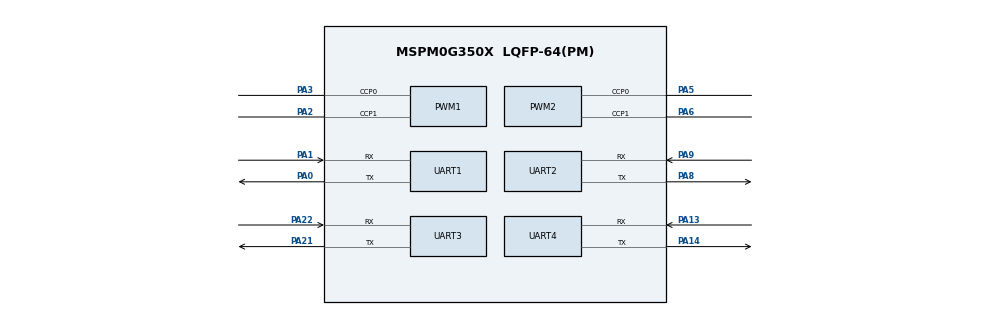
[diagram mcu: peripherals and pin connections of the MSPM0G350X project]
/**
 * @cliArgs --device "MSPM0G350X" --part "Default" --package "LQFP-64(PM)" --product "mspm0_sdk@2.05.01.00"
 * @versions {"tool":"1.24.1+4189"}
 */

/**
 * Import the modules used in this configuration.
 */
const ADC12   = scripting.addModule("/ti/driverlib/ADC12", {}, false);
const ADC121  = ADC12.addInstance();
const GPIO    = scripting.addModule("/ti/driverlib/GPIO", {}, false);
const GPIO1   = GPIO.addInstance();
const GPIO2   = GPIO.addInstance();
const GPIO3   = GPIO.addInstance();
const GPIO4   = GPIO.addInstance();
const PWM     = scripting.addModule("/ti/driverlib/PWM", {}, false);
const PWM1    = PWM.addInstance();
const PWM2    = PWM.addInstance();
const SYSCTL  = scripting.addModule("/ti/driverlib/SYSCTL");
const SYSTICK = scripting.addModule("/ti/driverlib/SYSTICK");
const TIMER   = scripting.addModule("/ti/driverlib/TIMER", {}, false);
const TIMER1  = TIMER.addInstance();
const TIMER2  = TIMER.addInstance();
const UART    = scripting.addModule("/ti/driverlib/UART", {}, false);
const UART1   = UART.addInstance();
const UART2   = UART.addInstance();
const UART3   = UART.addInstance();
const UART4   = UART.addInstance();
const WWDT    = scripting.addModule("/ti/driverlib/WWDT", {}, false);
const WWDT1   = WWDT.addInstance();

/**
 * Write custom configuration values to the imported modules.
 */
const divider6       = system.clockTree["PLL_CLK2X_DIV"];
divider6.divideValue = 4;

const divider7       = system.clockTree["PLL_PDIV"];
divider7.divideValue = 2;

const divider9       = system.clockTree["UDIV"];
divider9.divideValue = 2;

const multiplier2         = system.clockTree["PLL_QDIV"];
multiplier2.multiplyValue = 10;

const mux8       = system.clockTree["HSCLKMUX"];
mux8.inputSelect = "HSCLKMUX_SYSPLL2X";

ADC121.$name                 = "ADC12_0";
ADC121.repeatMode            = true;
ADC121.samplingOperationMode = "sequence";
ADC121.adcMem1chansel        = "DL_ADC12_INPUT_CHAN_1";
ADC121.sampleTime0           = "1 ms";
ADC121.enabledInterrupts     = ["DL_ADC12_INTERRUPT_MEM1_RESULT_LOADED"];
ADC121.endAdd                = 3;
ADC121.adcMem2chansel        = "DL_ADC12_INPUT_CHAN_2";
ADC121.adcMem3chansel        = "DL_ADC12_INPUT_CHAN_3";
ADC121.adcPin0Config.$name   = "ti_driverlib_gpio_GPIOPinGeneric4";
ADC121.adcPin1Config.$name   = "ti_driverlib_gpio_GPIOPinGeneric5";
ADC121.adcPin2Config.$name   = "ti_driverlib_gpio_GPIOPinGeneric10";
ADC121.peripheral.$assign    = "ADC0";
ADC121.adcPin3Config.$name   = "ti_driverlib_gpio_GPIOPinGeneric11";

const Board = scripting.addModule("/ti/driverlib/Board", {}, false);

GPIO1.port                               = "PORTB";
GPIO1.$name                              = "LED";
GPIO1.associatedPins[0].initialValue     = "SET";
GPIO1.associatedPins[0].internalResistor = "PULL_DOWN";
GPIO1.associatedPins[0].$name            = "D1";
GPIO1.associatedPins[0].assignedPin      = "14";

GPIO2.$name                              = "KEY";
GPIO2.port                               = "PORTB";
GPIO2.associatedPins[0].direction        = "INPUT";
GPIO2.associatedPins[0].assignedPin      = "21";
GPIO2.associatedPins[0].$name            = "S2";
GPIO2.associatedPins[0].internalResistor = "PULL_UP";

GPIO3.port                          = "PORTA";
GPIO3.$name                         = "EncoderA";
GPIO3.associatedPins[0].assignedPin = "4";
GPIO3.associatedPins[0].direction   = "INPUT";
GPIO3.associatedPins[0].interruptEn = true;
GPIO3.associatedPins[0].polarity    = "RISE_FALL";
GPIO3.associatedPins[0].$name       = "PIN_A";

GPIO4.$name                         = "EncoderB";
GPIO4.port                          = "PORTA";
GPIO4.associatedPins[0].direction   = "INPUT";
GPIO4.associatedPins[0].$name       = "PIN_B";
GPIO4.associatedPins[0].assignedPin = "7";
GPIO4.associatedPins[0].interruptEn = true;
GPIO4.associatedPins[0].polarity    = "RISE_FALL";

PWM1.$name                      = "PWM_0";
PWM1.peripheral.$assign         = "TIMG7";
PWM1.peripheral.ccp0Pin.$assign = "PA3";
PWM1.peripheral.ccp1Pin.$assign = "PA2";
PWM1.PWM_CHANNEL_0.$name        = "ti_driverlib_pwm_PWMTimerCC0";
PWM1.PWM_CHANNEL_1.$name        = "ti_driverlib_pwm_PWMTimerCC1";
PWM1.ccp0PinConfig.$name        = "ti_driverlib_gpio_GPIOPinGeneric12";
PWM1.ccp1PinConfig.$name        = "ti_driverlib_gpio_GPIOPinGeneric13";

PWM2.$name                      = "PWM_1";
PWM2.peripheral.$assign         = "TIMG6";
PWM2.peripheral.ccp0Pin.$assign = "PA5";
PWM2.peripheral.ccp1Pin.$assign = "PA6";
PWM2.PWM_CHANNEL_0.$name        = "ti_driverlib_pwm_PWMTimerCC2";
PWM2.PWM_CHANNEL_1.$name        = "ti_driverlib_pwm_PWMTimerCC3";
PWM2.ccp0PinConfig.$name        = "ti_driverlib_gpio_GPIOPinGeneric14";
PWM2.ccp1PinConfig.$name        = "ti_driverlib_gpio_GPIOPinGeneric15";

SYSCTL.forceDefaultClkConfig = true;
SYSCTL.clockTreeEn           = true;
scripting.suppress("For best practices when the CPUCLK is running at 32MHz and above, clear the flash status bit using DL_FlashCTL_executeClearStatus\\(\\) before executing any flash operation\\. Otherwise there may be false positives\\.", SYSCTL);

SYSTICK.periodEnable      = true;
SYSTICK.interruptEnable   = true;
SYSTICK.interruptPriority = "0";
SYSTICK.systickEnable     = true;
SYSTICK.period            = 80000;

TIMER1.$name              = "TIMER_1ms";
TIMER1.timerMode          = "PERIODIC_UP";
TIMER1.timerPeriod        = "1 ms";
TIMER1.timerStartTimer    = true;
TIMER1.interrupts         = ["ZERO"];
TIMER1.timerClkDiv        = 2;
TIMER1.peripheral.$assign = "TIMA0";

TIMER2.$name            = "TIMER_1s";
TIMER2.timerMode        = "PERIODIC_UP";
TIMER2.timerClkDiv      = 8;
TIMER2.timerClkPrescale = 200;
TIMER2.timerPeriod      = "1s";
TIMER2.timerStartTimer  = true;
TIMER2.interrupts       = ["ZERO"];

UART1.$name                    = "UART_0";
UART1.enabledInterrupts        = ["RX"];
UART1.peripheral.$assign       = "UART0";
UART1.peripheral.rxPin.$assign = "PA1";
UART1.peripheral.txPin.$assign = "PA0";
UART1.txPinConfig.$name        = "ti_driverlib_gpio_GPIOPinGeneric0";
UART1.rxPinConfig.$name        = "ti_driverlib_gpio_GPIOPinGeneric1";

UART2.$name                    = "UART_1";
UART2.enabledInterrupts        = ["RX"];
UART2.peripheral.$assign       = "UART1";
UART2.peripheral.rxPin.$assign = "PA9";
UART2.peripheral.txPin.$assign = "PA8";
UART2.txPinConfig.$name        = "ti_driverlib_gpio_GPIOPinGeneric2";
UART2.rxPinConfig.$name        = "ti_driverlib_gpio_GPIOPinGeneric3";

UART3.$name                    = "UART_2";
UART3.peripheral.$assign       = "UART2";
UART3.peripheral.rxPin.$assign = "PA22";
UART3.peripheral.txPin.$assign = "PA21";
UART3.txPinConfig.$name        = "ti_driverlib_gpio_GPIOPinGeneric6";
UART3.rxPinConfig.$name        = "ti_driverlib_gpio_GPIOPinGeneric7";

UART4.$name                    = "UART_3";
UART4.peripheral.$assign       = "UART3";
UART4.peripheral.rxPin.$assign = "PA13";
UART4.peripheral.txPin.$assign = "PA14";
UART4.txPinConfig.$name        = "ti_driverlib_gpio_GPIOPinGeneric8";
UART4.rxPinConfig.$name        = "ti_driverlib_gpio_GPIOPinGeneric9";

WWDT1.$name       = "WWDT0";
WWDT1.periodCount = "15";
WWDT1.sleepMode   = true;

/**
 * Pinmux solution for unlocked pins/peripherals. This ensures that minor changes to the automatic solver in a future
 * version of the tool will not impact the pinmux you originally saw.  These lines can be completely deleted in order to
 * re-solve from scratch.
 */
ADC121.peripheral.adcPin0.$suggestSolution   = "PA27";
ADC121.peripheral.adcPin1.$suggestSolution   = "PA26";
ADC121.peripheral.adcPin2.$suggestSolution   = "PA25";
ADC121.peripheral.adcPin3.$suggestSolution   = "PA24";
Board.peripheral.$suggestSolution            = "DEBUGSS";
Board.peripheral.swclkPin.$suggestSolution   = "PA20";
Board.peripheral.swdioPin.$suggestSolution   = "PA19";
GPIO1.associatedPins[0].pin.$suggestSolution = "PB14";
GPIO2.associatedPins[0].pin.$suggestSolution = "PB21";
GPIO3.associatedPins[0].pin.$suggestSolution = "PA4";
GPIO4.associatedPins[0].pin.$suggestSolution = "PA7";
TIMER2.peripheral.$suggestSolution           = "TIMA1";
WWDT1.peripheral.$suggestSolution            = "WWDT0";
